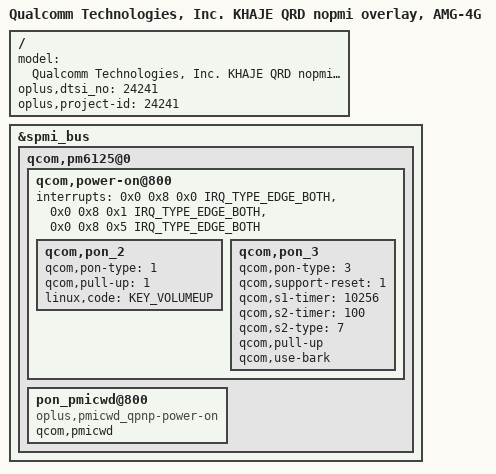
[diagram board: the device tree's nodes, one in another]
/dts-v1/;
/plugin/;

#include "../qcom/khaje-qrd-nopmi-overlay.dts"
#include "khaje_overlay_common.dtsi"
#include "AMG-4G_overlay_common.dtsi"
#include "nfc/AMG-4G-nfc-pn560.dtsi"
#include "sensor/AMG-4G-24241-sensor-mtp.dtsi"
#include "oplus_chg/oplus-chg-24241-24242.dtsi"
#include "oplus_chg/oplus-chg-24241-pps.dtsi"
#include "oplus_breathing/amg-4g-breathing_leds.dtsi"

/ {
    model = "Qualcomm Technologies, Inc. KHAJE QRD nopmi overlay, AMG-4G";
    oplus,dtsi_no = <24241>;
    oplus,project-id = <24241>;
};
&spmi_bus {
	qcom,pm6125@0 {
		qcom,power-on@800 {
			interrupts = <0x0 0x8 0x0 IRQ_TYPE_EDGE_BOTH>,
						 <0x0 0x8 0x1 IRQ_TYPE_EDGE_BOTH>,
						 <0x0 0x8 0x5 IRQ_TYPE_EDGE_BOTH>;
			interrupt-names = "kpdpwr", "resin", "kpdpwr-resin-bark";

			qcom,pon_2 {
				qcom,pon-type = <1>;
				qcom,pull-up = <1>;
				linux,code = <KEY_VOLUMEUP>;
			};

			qcom,pon_3 {
				qcom,pon-type = <3>;
				qcom,support-reset = <1>;
				qcom,s1-timer = <10256>;
				qcom,s2-timer = <100>;
				qcom,s2-type = <7>;
				qcom,pull-up;
				qcom,use-bark;
			};
		};

		pon_pmicwd@800 {
			compatible = "oplus,pmicwd_qpnp-power-on";
			qcom,pmicwd;
		};
	};
};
